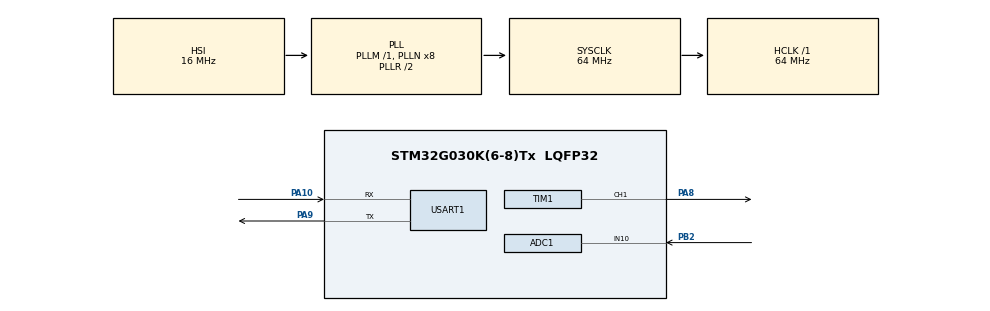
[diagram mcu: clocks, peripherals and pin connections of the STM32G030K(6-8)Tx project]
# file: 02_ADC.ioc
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ADC1.Channel-0\#ChannelRegularConversion=ADC_CHANNEL_10
ADC1.ContinuousConvMode=ENABLE
ADC1.DMAContinuousRequests=ENABLE
ADC1.NbrOfConversion=1
ADC1.NbrOfConversionFlag=1
ADC1.Rank-0\#ChannelRegularConversion=1
ADC1.SamplingTime-0\#ChannelRegularConversion=ADC_SAMPLINGTIME_COMMON_1
ADC1.SamplingTimeCommon1=ADC_SAMPLETIME_160CYCLES_5
ADC1.SelectedChannel=ADC_CHANNEL_10
ADC1.master=1
Dma.ADC1.0.Direction=DMA_PERIPH_TO_MEMORY
Dma.ADC1.0.EventEnable=DISABLE
Dma.ADC1.0.Instance=DMA1_Channel1
Dma.ADC1.0.MemDataAlignment=DMA_MDATAALIGN_HALFWORD
Dma.ADC1.0.MemInc=DMA_MINC_ENABLE
Dma.ADC1.0.Mode=DMA_CIRCULAR
Dma.ADC1.0.PeriphDataAlignment=DMA_PDATAALIGN_HALFWORD
Dma.ADC1.0.PeriphInc=DMA_PINC_DISABLE
Dma.ADC1.0.Polarity=HAL_DMAMUX_REQ_GEN_RISING
Dma.ADC1.0.Priority=DMA_PRIORITY_LOW
Dma.ADC1.0.RequestNumber=1
Dma.ADC1.0.SignalID=NONE
Dma.ADC1.0.SyncEnable=DISABLE
Dma.ADC1.0.SyncPolarity=HAL_DMAMUX_SYNC_NO_EVENT
Dma.ADC1.0.SyncRequestNumber=1
Dma.ADC1.0.SyncSignalID=NONE
Dma.Request0=ADC1
Mcu.Family=STM32G0
Mcu.Name=STM32G030K(6-8)Tx
Mcu.Package=LQFP32
NVIC.DMA1_Channel1_IRQn=true\:0\:0\:false\:false\:true\:false\:true\:true
PA10.Mode=Asynchronous
PA10.Signal=USART1_RX
PA13.Mode=Serial_Wire
PA13.Signal=SYS_SWDIO
PA14-BOOT0.Mode=Serial_Wire
PA14-BOOT0.Signal=SYS_SWCLK
PA8.Signal=S_TIM1_CH1
PA9.Mode=Asynchronous
PA9.Signal=USART1_TX
PB2.Mode=IN10
PB2.Signal=ADC1_IN10
PC14-OSC32_IN\ (PC14).Mode=HSE-External-Clock-Source
PC14-OSC32_IN\ (PC14).Signal=RCC_OSC_IN
PC15-OSC32_OUT\ (PC15).Mode=OSC enable
PC15-OSC32_OUT\ (PC15).Signal=RCC_OSC_EN
ProjectManager.HeapSize=0x200
ProjectManager.StackSize=0x400
ProjectManager.TargetToolchain=CMake
RCC.ADCFreq_Value=64000000
RCC.AHBFreq_Value=64000000
RCC.CortexFreq_Value=64000000
RCC.EXTERNAL_CLOCK_VALUE=12288000
RCC.HCLKFreq_Value=64000000
RCC.HSE_VALUE=8000000
RCC.HSI_VALUE=16000000
RCC.LSE_VALUE=32768
RCC.SYSCLKFreq_VALUE=64000000
RCC.SYSCLKSource=RCC_SYSCLKSOURCE_PLLCLK
RCC.VCOOutputFreq_Value=128000000
SH.S_TIM1_CH1.0=TIM1_CH1,PWM Generation1 CH1
TIM1.AutoReloadPreload=TIM_AUTORELOAD_PRELOAD_ENABLE
TIM1.Channel-PWM\ Generation1\ CH1=TIM_CHANNEL_1
USART1.VirtualMode-Asynchronous=VM_ASYNC
VP_TIM1_VS_ClockSourceINT.Mode=Internal
board=custom

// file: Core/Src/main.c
/* USER CODE BEGIN Header */
/**
  ******************************************************************************
  * @file           : main.c
  * @brief          : Main program body
  ******************************************************************************
  * @attention
  *
  * Copyright (c) 2025 STMicroelectronics.
  * All rights reserved.
  *
  * This software is licensed under terms that can be found in the LICENSE file
  * in the root directory of this software component.
  * If no LICENSE file comes with this software, it is provided AS-IS.
  *
  ******************************************************************************
  */
/* USER CODE END Header */
#include "main.h"
#include "adc.h"
#include "dma.h"
#include "tim.h"
#include "usart.h"
#include "gpio.h"
#include <stdio.h>

/* USER CODE BEGIN PV */

uint32_t AD_RES = 0;
char MSG[256] = "INIT DONE";
uint8_t ADC_FLAG = 0;

float AD_Multi = 0.5;
uint16_t AD_RES_MAX = 4000;
uint16_t AD_RES_MIN = 1000;

/* USER CODE END PV */

void SystemClock_Config(void);

int main(void)
{

  /* MCU Configuration--------------------------------------------------------*/

  /* Reset of all peripherals, Initializes the Flash interface and the Systick. */
  HAL_Init();

  /* Configure the system clock */
  SystemClock_Config();

  /* Initialize all configured peripherals */
  MX_GPIO_Init();
  MX_DMA_Init();
  MX_ADC1_Init();
  MX_TIM1_Init();
  MX_USART1_UART_Init();
  /* USER CODE BEGIN 2 */

  HAL_TIM_PWM_Start(&htim1, TIM_CHANNEL_1);

  HAL_ADC_Start_DMA(&hadc1, &AD_RES, 2);

  //HAL_ADCEx_Calibration_Start(&hadc1);
  HAL_UART_Transmit(&huart1, (uint8_t*)(MSG), sizeof(MSG), 100);

  AD_Multi = (65535 / (AD_RES_MAX - AD_RES_MIN)) * 1000;

  /* USER CODE END 2 */

  /* Infinite loop */
  while (1)
  {
    if(ADC_FLAG == 1)
    {
      if(((uint16_t)AD_RES) > AD_RES_MAX)
      {
        AD_RES_MAX = ((uint16_t)AD_RES);
        AD_Multi = (65535 / (AD_RES_MAX - AD_RES_MIN)) * 1000;
      }
      if(((uint16_t)AD_RES) < AD_RES_MIN)
      {
        AD_RES_MIN = ((uint16_t)AD_RES);
        AD_Multi = (65535 / (AD_RES_MAX - AD_RES_MIN)) * 1000;
      }

    TIM1->CCR1 = ((AD_RES - AD_RES_MIN) * AD_Multi) / 1000;
    /*
    if(AD_RES < (AD_RES_MIN*2))
    {
//      TIM1->CCR1 = 0;
    }
    (
      (
        (
          (au32_IN - au32_INmin)
          *
          (au32_OUTmax - au32_OUTmin)
        )
        /
        (au32_INmax - au32_INmin)
      )
      + au32_OUTmin
    )

    */

//  TIM1->CCR1 = (((uint16_t)AD_RES) << 4);
    ADC_FLAG = 0;
    }

    sprintf(MSG,"AD_RES; ((uint16_t)AD_RES); AD_RES_MIN; AD_RES_MAX; TIM1->CCR1 =, %ld , %d, %d, %d, %ld\r\n", AD_RES, ((uint16_t)AD_RES), AD_RES_MIN, AD_RES_MAX, TIM1->CCR1 );
    HAL_UART_Transmit(&huart1, (uint8_t*)(MSG), sizeof(MSG), 100);

    HAL_Delay(10);
  }
}
/*
72877135
12345678
72615002
72352849

*/
void SystemClock_Config(void)
{
  RCC_OscInitTypeDef RCC_OscInitStruct = {0};
  RCC_ClkInitTypeDef RCC_ClkInitStruct = {0};

  /** Configure the main internal regulator output voltage
  */
  HAL_PWREx_ControlVoltageScaling(PWR_REGULATOR_VOLTAGE_SCALE1);

  /** Initializes the RCC Oscillators according to the specified parameters
  * in the RCC_OscInitTypeDef structure.
  */
  RCC_OscInitStruct.OscillatorType = RCC_OSCILLATORTYPE_HSI;
  RCC_OscInitStruct.HSIState = RCC_HSI_ON;
  RCC_OscInitStruct.HSIDiv = RCC_HSI_DIV1;
  RCC_OscInitStruct.HSICalibrationValue = RCC_HSICALIBRATION_DEFAULT;
  RCC_OscInitStruct.PLL.PLLState = RCC_PLL_ON;
  RCC_OscInitStruct.PLL.PLLSource = RCC_PLLSOURCE_HSI;
  RCC_OscInitStruct.PLL.PLLM = RCC_PLLM_DIV1;
  RCC_OscInitStruct.PLL.PLLN = 8;
  RCC_OscInitStruct.PLL.PLLP = RCC_PLLP_DIV2;
  RCC_OscInitStruct.PLL.PLLR = RCC_PLLR_DIV2;
  if (HAL_RCC_OscConfig(&RCC_OscInitStruct) != HAL_OK)
  {
    Error_Handler();
  }

  /** Initializes the CPU, AHB and APB buses clocks
  */
  RCC_ClkInitStruct.ClockType = RCC_CLOCKTYPE_HCLK|RCC_CLOCKTYPE_SYSCLK
                              |RCC_CLOCKTYPE_PCLK1;
  RCC_ClkInitStruct.SYSCLKSource = RCC_SYSCLKSOURCE_PLLCLK;
  RCC_ClkInitStruct.AHBCLKDivider = RCC_SYSCLK_DIV1;
  RCC_ClkInitStruct.APB1CLKDivider = RCC_HCLK_DIV1;

  if (HAL_RCC_ClockConfig(&RCC_ClkInitStruct, FLASH_LATENCY_2) != HAL_OK)
  {
    Error_Handler();
  }
}

/* USER CODE BEGIN 4 */

void HAL_ADC_ConvCpltCallback(ADC_HandleTypeDef* hadc)
{
  ADC_FLAG = 1;
}

/* USER CODE END 4 */

void Error_Handler(void)
{
  __disable_irq();
  while (1)
  {
  }
}
